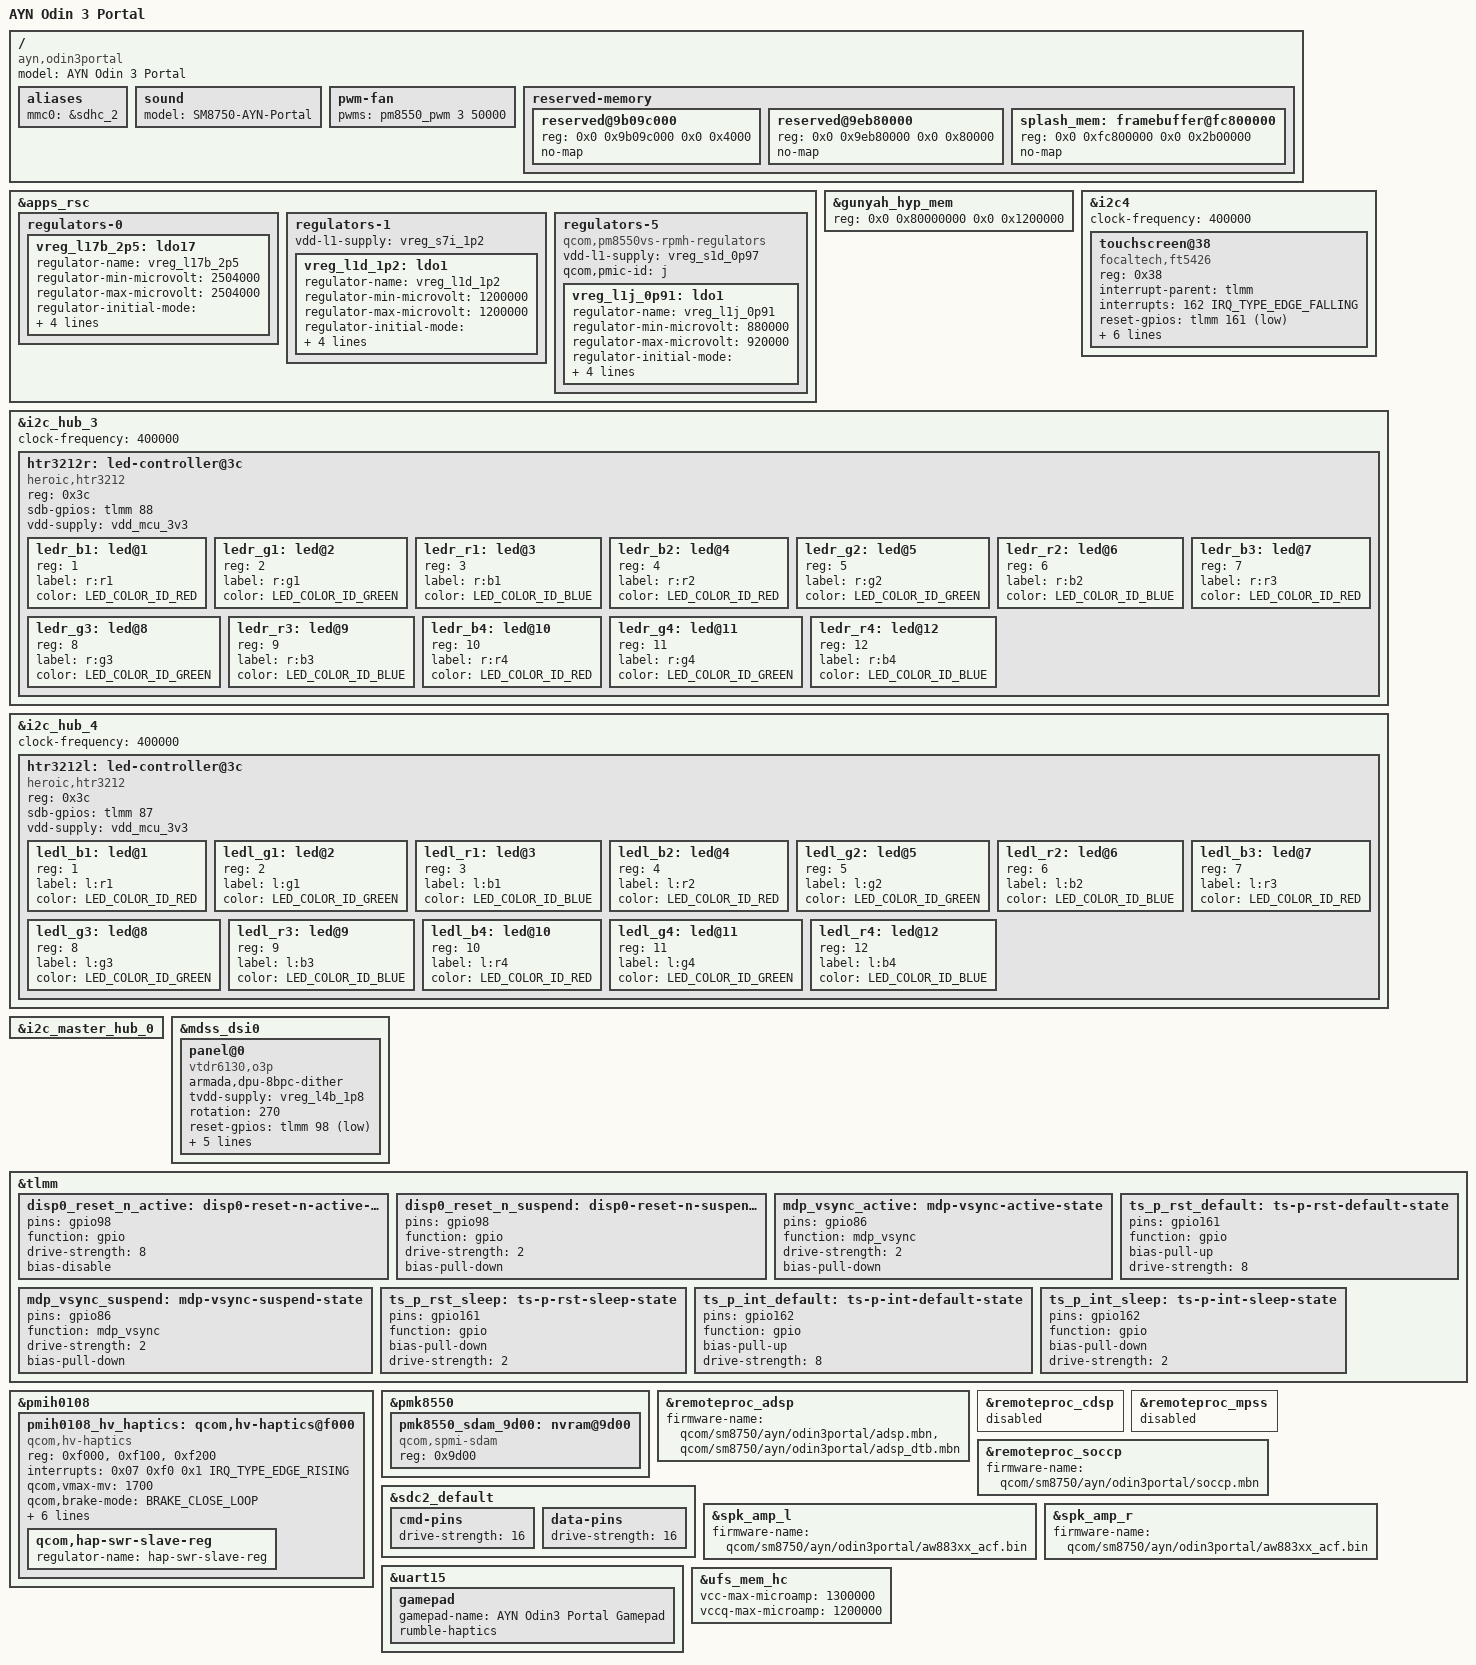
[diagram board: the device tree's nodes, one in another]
// SPDX-License-Identifier: BSD-3-Clause
/*
 * Copyright (c) 2026 Teguh Sobirin.
 * Copyright (c) 2026 Armada contributors.
 */

/dts-v1/;

#include <dt-bindings/input/qcom,hv-haptics.h>
#include "cq8725s-ayn-common.dtsi"

/* cpusys_vm_mem EXISTE en nuestro sm8750.dtsi (labels comprobados 11/11/2026). */
/delete-node/ &cpusys_vm_mem;

/ {
	model = "AYN Odin 3 Portal";
	compatible = "ayn,odin3portal", "qcom,cq8725s", "qcom,sm8750";

	aliases {
		mmc0 = &sdhc_2;
	};

	sound {
		model = "SM8750-AYN-Portal";
	};

	pwm-fan {
		pwms = <&pm8550_pwm 3 50000>;
	};

	reserved-memory {
		reserved@9b09c000 {
			reg = <0x0 0x9b09c000 0x0 0x4000>;
			no-map;
		};

		reserved@9eb80000 {
			reg = <0x0 0x9eb80000 0x0 0x80000>;
			no-map;
		};

		splash_mem: framebuffer@fc800000 {
			reg = <0x0 0xfc800000 0x0 0x2b00000>;
			no-map;
		};
	};
};

&apps_rsc {
	regulators-0 {
		vreg_l17b_2p5: ldo17 {
			regulator-name = "vreg_l17b_2p5";
			regulator-min-microvolt = <2504000>;
			regulator-max-microvolt = <2504000>;
			regulator-initial-mode = <RPMH_REGULATOR_MODE_HPM>;
			regulator-allow-set-load;
			regulator-allowed-modes = <RPMH_REGULATOR_MODE_LPM
						   RPMH_REGULATOR_MODE_HPM>;
		};
	};

	regulators-1 {
		vdd-l1-supply = <&vreg_s7i_1p2>;

		vreg_l1d_1p2: ldo1 {
			regulator-name = "vreg_l1d_1p2";
			regulator-min-microvolt = <1200000>;
			regulator-max-microvolt = <1200000>;
			regulator-initial-mode = <RPMH_REGULATOR_MODE_HPM>;
			regulator-allow-set-load;
			regulator-allowed-modes = <RPMH_REGULATOR_MODE_LPM
						   RPMH_REGULATOR_MODE_HPM>;
		};
	};

	regulators-5 {
		compatible = "qcom,pm8550vs-rpmh-regulators";

		vdd-l1-supply = <&vreg_s1d_0p97>;

		qcom,pmic-id = "j";

		vreg_l1j_0p91: ldo1 {
			regulator-name = "vreg_l1j_0p91";
			regulator-min-microvolt = <880000>;
			regulator-max-microvolt = <920000>;
			regulator-initial-mode = <RPMH_REGULATOR_MODE_HPM>;
			regulator-allow-set-load;
			regulator-allowed-modes = <RPMH_REGULATOR_MODE_LPM
						   RPMH_REGULATOR_MODE_HPM>;
		};
	};
};

&gunyah_hyp_mem {
	reg = <0x0 0x80000000 0x0 0x1200000>;
};

&i2c4 {
	clock-frequency = <400000>;
	status = "okay";

	/*
	 * ADAPTACION A NUESTRO ARBOL: en Armada este nodo vive en su
	 * cq8725s-ayn-common.dtsi; en el nuestro esta en cq8725s-ayn-odin3.dts.
	 * El DTS de la Portal solo cambiaba el compatible, asi que se trae el
	 * nodo completo (mismos GPIOs/rails que la Odin 3) para no dejarlo vacio.
	 * FT5452: provisional use of the family FT5x06 protocol.
	 */
	touchscreen@38 {
		compatible = "focaltech,ft5426";
		reg = <0x38>;
		#address-cells = <1>;
		#size-cells = <0>;

		interrupt-parent = <&tlmm>;
		interrupts = <162 IRQ_TYPE_EDGE_FALLING>;

		reset-gpios = <&tlmm 161 GPIO_ACTIVE_LOW>;

		vcc-supply = <&vreg_l14b_3p2>;
		iovcc-supply = <&vreg_l12b_1p8>;

		pinctrl-0 = <&ts_p_rst_default &ts_p_int_default>;
		pinctrl-1 = <&ts_p_rst_sleep &ts_p_int_sleep>;
		pinctrl-names = "default", "sleep";

		touchscreen-size-x = <1080>;
		touchscreen-size-y = <1920>;
	};
};

&i2c_hub_3 {
	clock-frequency = <400000>;
	status = "okay";

	htr3212r: led-controller@3c {
		compatible = "heroic,htr3212";
		reg = <0x3c>;
		#address-cells = <1>;
		#size-cells = <0>;
		sdb-gpios = <&tlmm 88 GPIO_ACTIVE_HIGH>;
		vdd-supply = <&vdd_mcu_3v3>;

		ledr_b1: led@1 {
			reg = <1>;
			label = "r:r1";
			color = <LED_COLOR_ID_RED>;
		};

		ledr_g1: led@2 {
			reg = <2>;
			label = "r:g1";
			color = <LED_COLOR_ID_GREEN>;
		};

		ledr_r1: led@3 {
			reg = <3>;
			label = "r:b1";
			color = <LED_COLOR_ID_BLUE>;
		};

		ledr_b2: led@4 {
			reg = <4>;
			label = "r:r2";
			color = <LED_COLOR_ID_RED>;
		};

		ledr_g2: led@5 {
			reg = <5>;
			label = "r:g2";
			color = <LED_COLOR_ID_GREEN>;
		};

		ledr_r2: led@6 {
			reg = <6>;
			label = "r:b2";
			color = <LED_COLOR_ID_BLUE>;
		};

		ledr_b3: led@7 {
			reg = <7>;
			label = "r:r3";
			color = <LED_COLOR_ID_RED>;
		};

		ledr_g3: led@8 {
			reg = <8>;
			label = "r:g3";
			color = <LED_COLOR_ID_GREEN>;
		};

		ledr_r3: led@9 {
			reg = <9>;
			label = "r:b3";
			color = <LED_COLOR_ID_BLUE>;
		};

		ledr_b4: led@10 {
			reg = <10>;
			label = "r:r4";
			color = <LED_COLOR_ID_RED>;
		};

		ledr_g4: led@11 {
			reg = <11>;
			label = "r:g4";
			color = <LED_COLOR_ID_GREEN>;
		};

		ledr_r4: led@12 {
			reg = <12>;
			label = "r:b4";
			color = <LED_COLOR_ID_BLUE>;
		};
	};
};

&i2c_hub_4 {
	clock-frequency = <400000>;
	status = "okay";

	htr3212l: led-controller@3c {
		compatible = "heroic,htr3212";
		reg = <0x3c>;
		#address-cells = <1>;
		#size-cells = <0>;
		sdb-gpios = <&tlmm 87 GPIO_ACTIVE_HIGH>;
		vdd-supply = <&vdd_mcu_3v3>;

		ledl_b1: led@1 {
			reg = <1>;
			label = "l:r1";
			color = <LED_COLOR_ID_RED>;
		};

		ledl_g1: led@2 {
			reg = <2>;
			label = "l:g1";
			color = <LED_COLOR_ID_GREEN>;
		};

		ledl_r1: led@3 {
			reg = <3>;
			label = "l:b1";
			color = <LED_COLOR_ID_BLUE>;
		};

		ledl_b2: led@4 {
			reg = <4>;
			label = "l:r2";
			color = <LED_COLOR_ID_RED>;
		};

		ledl_g2: led@5 {
			reg = <5>;
			label = "l:g2";
			color = <LED_COLOR_ID_GREEN>;
		};

		ledl_r2: led@6 {
			reg = <6>;
			label = "l:b2";
			color = <LED_COLOR_ID_BLUE>;
		};

		ledl_b3: led@7 {
			reg = <7>;
			label = "l:r3";
			color = <LED_COLOR_ID_RED>;
		};

		ledl_g3: led@8 {
			reg = <8>;
			label = "l:g3";
			color = <LED_COLOR_ID_GREEN>;
		};

		ledl_r3: led@9 {
			reg = <9>;
			label = "l:b3";
			color = <LED_COLOR_ID_BLUE>;
		};

		ledl_b4: led@10 {
			reg = <10>;
			label = "l:r4";
			color = <LED_COLOR_ID_RED>;
		};

		ledl_g4: led@11 {
			reg = <11>;
			label = "l:g4";
			color = <LED_COLOR_ID_GREEN>;
		};

		ledl_r4: led@12 {
			reg = <12>;
			label = "l:b4";
			color = <LED_COLOR_ID_BLUE>;
		};
	};
};

&i2c_master_hub_0 {
	status = "okay";
};

&mdss_dsi0 {
	/*
	 * ADAPTACION A NUESTRO ARBOL: Armada define reset-gpios/vddio/pinctrl en su
	 * cq8725s-ayn-common.dtsi; en el nuestro ese nodo es minimo (reg, dither,
	 * port) y la Odin 3 los pone en su .dts. Se replican aqui los mismos, pero
	 * se dejan fuera vci/vdd/disp/blvdd: el driver de Armada para este panel
	 * (parche 2160) pide vddio + tvdd, no los rails de la ICNA3520.
	 */
	panel@0 {
		compatible = "vtdr6130,o3p";
		armada,dpu-8bpc-dither;
		tvdd-supply = <&vreg_l4b_1p8>;
		rotation = <270>;

		reset-gpios = <&tlmm 98 GPIO_ACTIVE_LOW>;

		vddio-supply = <&vreg_l12b_1p8>;

		pinctrl-0 = <&disp0_reset_n_active>, <&mdp_vsync_active>;
		pinctrl-1 = <&disp0_reset_n_suspend>, <&mdp_vsync_suspend>;
		pinctrl-names = "default", "sleep";
	};
};

/*
 * ADAPTACION A NUESTRO ARBOL: estos pinctrl viven en cq8725s-ayn-odin3.dts
 * (en Armada estan en el dtsi comun). Mismos GPIOs que la Odin 3.
 */
&tlmm {
	disp0_reset_n_active: disp0-reset-n-active-state {
		pins = "gpio98";
		function = "gpio";
		drive-strength = <8>;
		bias-disable;
	};

	disp0_reset_n_suspend: disp0-reset-n-suspend-state {
		pins = "gpio98";
		function = "gpio";
		drive-strength = <2>;
		bias-pull-down;
	};

	mdp_vsync_active: mdp-vsync-active-state {
		pins = "gpio86";
		function = "mdp_vsync";
		drive-strength = <2>;
		bias-pull-down;
	};

	mdp_vsync_suspend: mdp-vsync-suspend-state {
		pins = "gpio86";
		function = "mdp_vsync";
		drive-strength = <2>;
		bias-pull-down;
	};

	ts_p_rst_default: ts-p-rst-default-state {
		pins = "gpio161";
		function = "gpio";
		bias-pull-up;
		drive-strength = <8>;
	};

	ts_p_rst_sleep: ts-p-rst-sleep-state {
		pins = "gpio161";
		function = "gpio";
		bias-pull-down;
		drive-strength = <2>;
	};

	ts_p_int_default: ts-p-int-default-state {
		pins = "gpio162";
		function = "gpio";
		bias-pull-up;
		drive-strength = <8>;
	};

	ts_p_int_sleep: ts-p-int-sleep-state {
		pins = "gpio162";
		function = "gpio";
		bias-pull-down;
		drive-strength = <2>;
	};
};

&pmih0108 {
	pmih0108_hv_haptics: qcom,hv-haptics@f000 {
		compatible = "qcom,hv-haptics";
		reg = <0xf000>, <0xf100>, <0xf200>;
		interrupts = <0x07 0xf0 0x1 IRQ_TYPE_EDGE_RISING>;
		interrupt-names = "fifo-empty";
		qcom,vmax-mv = <1700>;
		qcom,brake-mode = <BRAKE_CLOSE_LOOP>;
		qcom,lra-period-us = <5880>;
		qcom,brake-pattern = /bits/ 8 <0xff 0x3f 0x1f>;
		qcom,drv-sig-shape = <WF_SINE>;
		qcom,brake-sig-shape = <WF_SINE>;
		nvmem-names = "hap_cfg_sdam";
		nvmem = <&pmk8550_sdam_9d00>;

		qcom,hap-swr-slave-reg {
			regulator-name = "hap-swr-slave-reg";
		};
	};
};

&pmk8550 {
	pmk8550_sdam_9d00: nvram@9d00 {
		compatible = "qcom,spmi-sdam";
		reg = <0x9d00>;
	};
};

&remoteproc_adsp {
	firmware-name = "qcom/sm8750/ayn/odin3portal/adsp.mbn",
			"qcom/sm8750/ayn/odin3portal/adsp_dtb.mbn";
};

&remoteproc_cdsp {
	status = "disabled";
};

&remoteproc_mpss {
	status = "disabled";
};

&remoteproc_soccp {
	firmware-name = "qcom/sm8750/ayn/odin3portal/soccp.mbn";
};

&sdc2_default {
	cmd-pins {
		drive-strength = <16>;
	};

	data-pins {
		drive-strength = <16>;
	};
};

&spk_amp_l {
	firmware-name = "qcom/sm8750/ayn/odin3portal/aw883xx_acf.bin";
};

&spk_amp_r {
	firmware-name = "qcom/sm8750/ayn/odin3portal/aw883xx_acf.bin";
};

&uart15 {
	gamepad {
		gamepad-name = "AYN Odin3 Portal Gamepad";
		rumble-haptics;
	};
};

&ufs_mem_hc {
	vcc-max-microamp = <1300000>;
	vccq-max-microamp = <1200000>;

	/delete-property/ resets;
	/delete-property/ reset-names;
};
